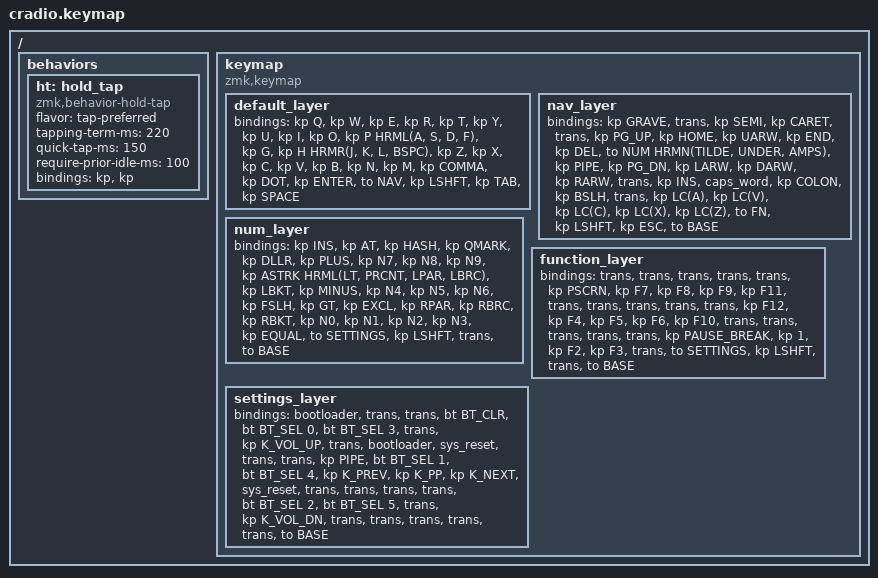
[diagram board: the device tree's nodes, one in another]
// Copyright (c) 2022 The ZMK Contributors
// SPDX-License-Identifier: MIT

#include <behaviors.dtsi>
#include <dt-bindings/zmk/keys.h>
#include <dt-bindings/zmk/bt.h>

// Home row mods macro
#define HRML(k1,k2,k3,k4) &ht LC(LS(LA(LGUI))) k1 &ht LGUI k2  &ht LALT k3  &ht LCTRL k4
#define HRMR(k1,k2,k3,k4) &ht RCTRL k1  &ht RALT k2  &ht RGUI k3  &ht LC(LS(LA(LGUI))) k4
#define HRMN(k1,k2,k3) &ht LGUI k1  &ht LALT k2  &ht LCTRL k3

#define BASE        0
#define NAV         1
#define NUM         2
#define FN          3
#define SETTINGS    4


/ {
    behaviors {
        ht: hold_tap {
            compatible = "zmk,behavior-hold-tap";
            #binding-cells = <2>;
            flavor = "tap-preferred";
            tapping-term-ms = <220>;
            quick-tap-ms = <150>;
            require-prior-idle-ms = <100>;
            bindings = <&kp>, <&kp>;
        };
    };

    //conditional_layers {
    //    compatible = "zmk,conditional-layers";
    //    tri_layer {
    //        if-layers = <1 2>;
    //        then-layer = <4>;
    //    };
    //};

    keymap {
        compatible = "zmk,keymap";
        default_layer {
            bindings = <
        //╭──────────┬──────────┬──────────┬──────────┬──────────╮   ╭──────────┬──────────┬──────────┬──────────┬──────────╮
        //│  Q       │  W       │  E       │  R       │  T       │   │  Y       │  U       │  I       │  O       │  P       │
            &kp Q      &kp W      &kp E      &kp R      &kp T          &kp Y      &kp U      &kp I      &kp O      &kp P
        //├──────────┼──────────┼──────────┼──────────┼──────────┤   ├──────────┼──────────┼──────────┼──────────┼──────────┤
        //│  A       │  S       │  D       │  F       │  G       │   │  H       │  J       │  K       │  L       │          │
            HRML(A,     S,         D,         F)        &kp G          &kp H      HRMR(J,     K,         L,        BSPC)
        //├──────────┼──────────┼──────────┼──────────┼──────────┤   ├──────────┼──────────┼──────────┼──────────┼──────────┤
        //│  Z       │  X       │  C       │  V       │  B       │   │  N       │  M       │ , <      │ . >      │          │
            &kp Z      &kp X      &kp C      &kp V      &kp B          &kp N      &kp M      &kp COMMA  &kp DOT    &kp ENTER 
        //╰──────────┴──────────┴──────────┼──────────┼──────────┤   ├──────────┼──────────┼──────────┴──────────┴──────────╯
                                             &to NAV    &kp LSHFT      &kp TAB   &kp SPACE
        //                                 ╰──────────┴──────────╯   ╰──────────┴──────────╯
            >;
        };

        nav_layer {
            bindings = <
        //╭──────────┬──────────┬──────────┬──────────┬──────────╮   ╭──────────┬──────────┬──────────┬──────────┬──────────╮
        //│  `       │          │  ;       │  ^       │          │   │  PAGE UP │  HOME    │  UP      │  END     │  DELETE  │
           &kp GRAVE   &trans     &kp SEMI   &kp CARET  &trans         &kp PG_UP  &kp HOME   &kp UARW   &kp END    &kp DEL   
        //├──────────┼──────────┼──────────┼──────────┼──────────┤   ├──────────┼──────────┼──────────┼──────────┼──────────┤
        //│  `       │  ~       │  _       │  &       │  |       │   │  PAGE DN │  LEFT    │  DOWN    │  RIGHT   │  BSPC    │
            &to NUM HRMN(TILDE,   UNDER,    AMPS)      &kp PIPE       &kp PG_DN  &kp LARW   &kp DARW   &kp RARW   &trans
        //├──────────┼──────────┼──────────┼──────────┼──────────┤   ├──────────┼──────────┼──────────┼──────────┼──────────┤
        //│ INSERT   │ CAPS     │  :       │  \       │          │   │ SEL ALL  │  PASTE   │  COPY    │  CUT     │  UNDO    │
            &kp INS    &caps_word &kp COLON  &kp BSLH   &trans         &kp LC(A)  &kp LC(V)  &kp LC(C)  &kp LC(X)  &kp LC(Z) 
        //╰──────────┴──────────┴──────────┼──────────┼──────────┤   ├──────────┼──────────┼──────────┴──────────┴──────────╯
                                             &to FN     &kp LSHFT      &kp ESC    &to BASE
        //                                 ╰──────────┴──────────╯   ╰──────────┴──────────╯
            >;
        };

        num_layer {
            bindings = <
        //╭──────────┬──────────┬──────────┬──────────┬──────────╮   ╭──────────┬──────────┬──────────┬──────────┬──────────╮
        //│  !       │  @       │  #       │  ?       │  $       │   │  +       │  7       │  8       │  9       │  *       │
            &kp INS    &kp AT     &kp HASH   &kp QMARK  &kp DLLR       &kp PLUS   &kp N7     &kp N8     &kp N9     &kp ASTRK 
        //├──────────┼──────────┼──────────┼──────────┼──────────┤   ├──────────┼──────────┼──────────┼──────────┼──────────┤
        //│  <       │  %       │  (       │  {       │  [       │   │  -       │  4       │  5       │  6       │  /       │
            HRML(LT,   PRCNT,     LPAR,      LBRC)      &kp LBKT       &kp MINUS  &kp N4     &kp N5     &kp N6     &kp FSLH  
        //├──────────┼──────────┼──────────┼──────────┼──────────┤   ├──────────┼──────────┼──────────┼──────────┼──────────┤
        //│  >       │  !       │  )       │  }       │  ]       │   │  0       │  1       │  2       │  3       │  =       │
            &kp GT     &kp EXCL   &kp RPAR   &kp RBRC   &kp RBKT       &kp N0     &kp N1     &kp N2     &kp N3     &kp EQUAL 
        //╰──────────┴──────────┴──────────┼──────────┼──────────┤   ├──────────┼──────────┼──────────┴──────────┴──────────╯
                                          &to SETTINGS  &kp LSHFT      &trans     &to BASE
        //                                 ╰──────────┴──────────╯   ╰──────────┴──────────╯
            >;
        };

        function_layer {
            bindings = <
        //╭──────────┬──────────┬──────────┬──────────┬──────────╮   ╭──────────┬──────────┬──────────┬──────────┬──────────╮
        //│          │          │          │          │          │   │ PRNT SCRN│   F7     │  F8      │   F9     │  F11     │
            &trans     &trans     &trans     &trans     &trans         &kp PSCRN  &kp F7     &kp F8     &kp F9     &kp F11   
        //├──────────┼──────────┼──────────┼──────────┼──────────┤   ├──────────┼──────────┼──────────┼──────────┼──────────┤
        //│          │          │          │          │          │   │  F12     │  F4      │  F5      │  F6      │  F10     │
            &trans     &trans     &trans     &trans     &trans         &kp F12    &kp F4     &kp F5     &kp F6     &kp F10   
        //├──────────┼──────────┼──────────┼──────────┼──────────┤   ├──────────┼──────────┼──────────┼──────────┼──────────┤
        //│          │          │          │          │          │   │  BREAK   │  F1      │  F2      │  F3      │          │
            &trans     &trans     &trans     &trans     &trans     &kp PAUSE_BREAK &kp 1      &kp F2     &kp F3     &trans    
        //╰──────────┴──────────┴──────────┼──────────┼──────────┤   ├──────────┼──────────┼──────────┴──────────┴──────────╯
                                           &to SETTINGS &kp LSHFT      &trans     &to BASE
        //                                 ╰──────────┴──────────╯   ╰──────────┴──────────╯
            >;
        };

        settings_layer {
            bindings = <
        //╭──────────┬──────────┬──────────┬──────────┬──────────╮   ╭──────────┬──────────┬──────────┬──────────┬──────────╮
        //│BOOTLOADER│          │          │ CLEAR BT │PROFILE 0 │   │PROFILE 3 │          │  VOL UP  │          │BOOTLOADER│
          &bootloader  &trans     &trans    &bt BT_CLR &bt BT_SEL 0  &bt BT_SEL 3 &trans   &kp K_VOL_UP &trans    &bootloader
        //├──────────┼──────────┼──────────┼──────────┼──────────┤   ├──────────┼──────────┼──────────┼──────────┼──────────┤
        //│  RESET   │          │          │   |      │PROFILE 1 │   │PROFILE 4 │  PREV    │  PLAY    │  NEXT    │  RESET   │
          &sys_reset   &trans     &trans    &kp PIPE   &bt BT_SEL 1  &bt BT_SEL 4 &kp K_PREV &kp K_PP  &kp K_NEXT  &sys_reset 
        //├──────────┼──────────┼──────────┼──────────┼──────────┤   ├──────────┼──────────┼──────────┼──────────┼──────────┤
        //│          │          │          │          │PROFILE 2 │   │PROFILE 5 │          │  VOL DN  │          │          │
            &trans     &trans     &trans     &trans    &bt BT_SEL 2  &bt BT_SEL 5 &trans   &kp K_VOL_DN &trans     &trans
        //╰──────────┴──────────┴──────────┼──────────┼──────────┤   ├──────────┼──────────┼──────────┴──────────┴──────────╯
                                             &trans     &trans         &trans     &to BASE
        //                                 ╰──────────┴──────────╯   ╰──────────┴──────────╯
            >;
        };
    };
};
